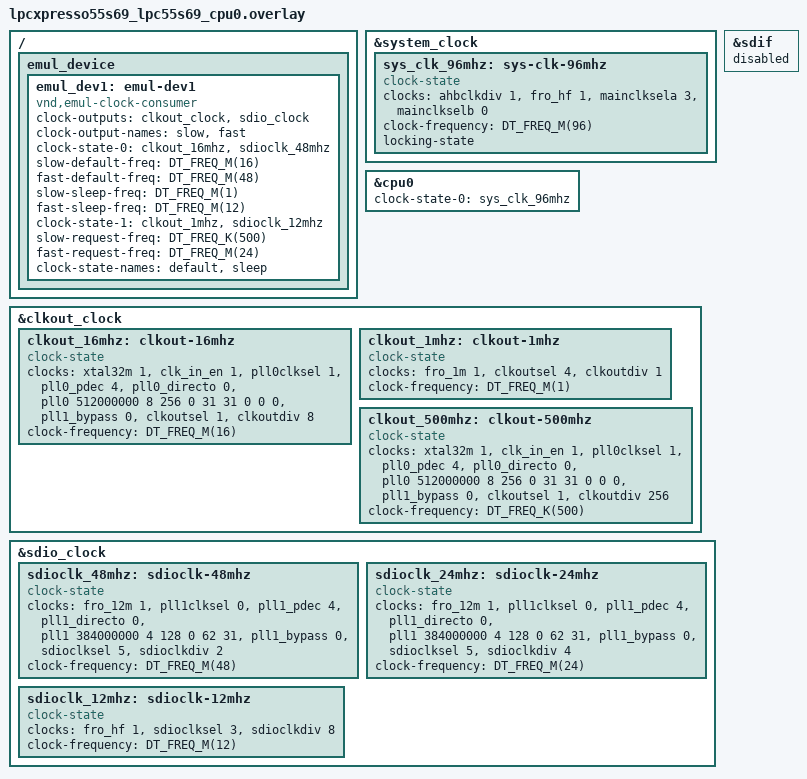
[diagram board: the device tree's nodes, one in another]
/*
 * Copyright (c) 2024 Tenstorrent AI ULC
 *
 * SPDX-License-Identifier: Apache-2.0
 */

#include <freq.h>

/* Clock CPU from FROHF, since we will use the PLLs within our testcases */
&system_clock {
	sys_clk_96mhz: sys-clk-96mhz {
		compatible = "clock-state";
		clocks = <&ahbclkdiv 1 &fro_hf 1 &mainclksela 3 &mainclkselb 0>;
		clock-frequency = <DT_FREQ_M(96)>;
		locking-state;
	};
};

&cpu0 {
	clock-state-0 = <&sys_clk_96mhz>;
};

/* Disable the SD controller- we are using its clock for this test */
&sdif {
	status = "disabled";
};

/* Define clock states for clockout clock */
&clkout_clock {
	clkout_16mhz: clkout-16mhz {
		compatible = "clock-state";
		/* Expect a clock frequency of 16 MHz */
		clocks = <&xtal32m 1 &clk_in_en 1 &pll0clksel 1
			&pll0_pdec 4 &pll0_directo 0
			&pll0 512000000 8 256 0 31 31 0 0 0
			&pll1_bypass 0 &clkoutsel 1
			&clkoutdiv 8>;
		clock-frequency = <DT_FREQ_M(16)>;
	};

	clkout_1mhz: clkout-1mhz {
		compatible = "clock-state";
		/* Expect a clock frequency of 1MHz */
		clocks = <&fro_1m 1 &clkoutsel 4 &clkoutdiv 1>;
		clock-frequency = <DT_FREQ_M(1)>;
	};

	clkout_500mhz: clkout-500mhz {
		compatible = "clock-state";
		/* Expect a clock frequency of 500 KHz */
		clocks = <&xtal32m 1 &clk_in_en 1 &pll0clksel 1
			&pll0_pdec 4 &pll0_directo 0
			&pll0 512000000 8 256 0 31 31 0 0 0
			&pll1_bypass 0 &clkoutsel 1
			&clkoutdiv 256>;
		clock-frequency = <DT_FREQ_K(500)>;
	};
};

/* Define clock states for SDIO clock */
&sdio_clock {
	sdioclk_48mhz: sdioclk-48mhz {
		compatible = "clock-state";
		/* Expect a clock frequency of 48 MHz */
		clocks = <&fro_12m 1 &pll1clksel 0
			&pll1_pdec 4 &pll1_directo 0
			&pll1 384000000 4 128 0 62 31
			&pll1_bypass 0 &sdioclksel 5
			&sdioclkdiv 2>;
		clock-frequency = <DT_FREQ_M(48)>;
	};

	sdioclk_24mhz: sdioclk-24mhz {
		compatible = "clock-state";
		/* Expect a clock frequency of 24 MHz */
		clocks = <&fro_12m 1 &pll1clksel 0
			&pll1_pdec 4 &pll1_directo 0
			&pll1 384000000 4 128 0 62 31
			&pll1_bypass 0 &sdioclksel 5
			&sdioclkdiv 4>;
		clock-frequency = <DT_FREQ_M(24)>;
	};

	sdioclk_12mhz: sdioclk-12mhz {
		compatible = "clock-state";
		/* Expect a clock frequency of 12 MHz */
		clocks = <&fro_hf 1 &sdioclksel 3
			&sdioclkdiv 8>;
		clock-frequency = <DT_FREQ_M(12)>;
	};
};

/ {
	/* Emulated device clock consumer */
	emul_device {
		emul_dev1: emul-dev1 {
			compatible = "vnd,emul-clock-consumer";
			clock-outputs = <&clkout_clock &sdio_clock>;
			clock-output-names = "slow", "fast";
			clock-state-0 = <&clkout_16mhz &sdioclk_48mhz>;
			slow-default-freq = <DT_FREQ_M(16)>;
			fast-default-freq = <DT_FREQ_M(48)>;
			slow-sleep-freq = <DT_FREQ_M(1)>;
			fast-sleep-freq = <DT_FREQ_M(12)>;
			clock-state-1 = <&clkout_1mhz &sdioclk_12mhz>;
			slow-request-freq = <DT_FREQ_K(500)>;
			fast-request-freq = <DT_FREQ_M(24)>;
			clock-state-names = "default", "sleep";
		};
	};
};
